# 2806x_CLA_Type0_Registers register map
Vendor: Texas Instruments
Peripheral module from a debugger description file (folder C2000).
Address unit: 16 bits
Registers are 16-bit, access not given, no defined reset value unless marked. A register's access mark holds for its fields unless they carry their own. Offsets are as the file gives them; lines under a group give offsets from that group; [hi:lo] are bit positions; {n}, {i} and the like mark numbered series; 'fields as' and 'values as' point back to an identical list; <NAME> marks a mode.

## CLA — CLA1 Registers
0x00 MVECT1 — Task 1 vector
0x01 MVECT2 — Task 2 vector
0x02 MVECT3 — Task 3 vector
0x03 MVECT4 — Task 4 vector
0x04 MVECT5 — Task 5 vector
0x05 MVECT6 — Task 6 vector
0x06 MVECT7 — Task 7 vector
0x07 MVECT8 — Task 8 vector
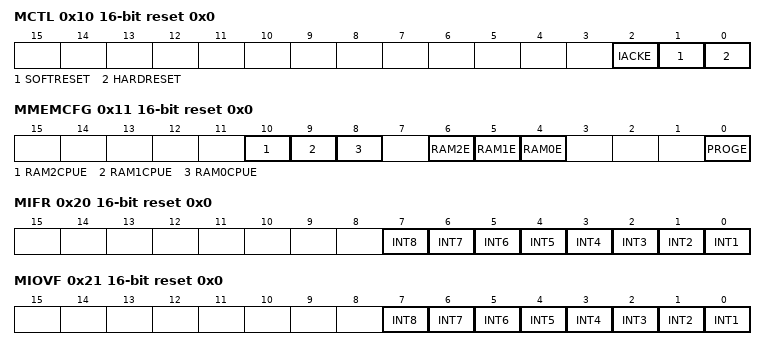
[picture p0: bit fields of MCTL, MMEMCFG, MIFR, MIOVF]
0x10 MCTL rw reset 0x0 — CLA control
  [2] IACKE — IACK enable
  [1] SOFTRESET
  [0] HARDRESET
0x11 MMEMCFG rw reset 0x0 — CLA memory configuration
  [10] RAM2CPUE — RAM2 CPU Access enable
  [9] RAM1CPUE — RAM1 CPU Access enable
  [8] RAM0CPUE — RAM0 CPU Access enable
  [6] RAM2E — RAM2 enable
  [5] RAM1E — RAM1 enable
  [4] RAM0E — RAM0 enable
  [0] PROGE — Program memory enable
0x14 MPISRCSEL1 32-bit — CLA interrupt source select
0x20 MIFR ro reset 0x0 — CLA interrupt flag
  [n-1] INT{n} (n=1..8) — Interrupt {n} flag bit
0x21 MIOVF ro reset 0x0 — CLA interrupt overflow flag
  [n-1] INT{n} (n=1..8) — Interrupt {n} overflow bit
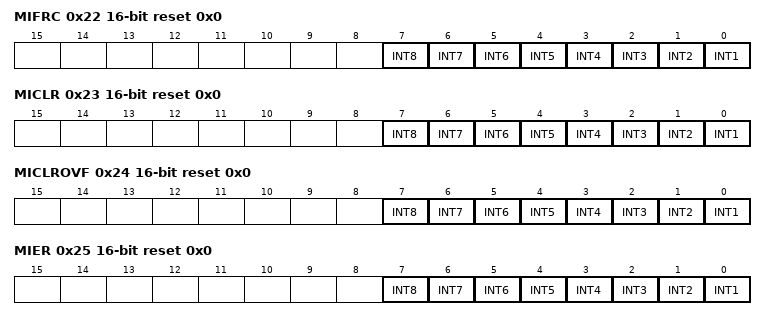
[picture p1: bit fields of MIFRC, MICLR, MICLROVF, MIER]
0x22 MIFRC rw reset 0x0 — CLA interrupt force
  [n-1] INT{n} (n=1..8) — Interrupt {n} force bit
0x23 MICLR rw reset 0x0 — CLA interrupt flag clear
  [n-1] INT{n} (n=1..8) — Interrupt {n} clear bit
0x24 MICLROVF rw reset 0x0 — CLA interrupt overflow flag clear
  [n-1] INT{n} (n=1..8) — Interrupt {n} overflow clear bit
0x25 MIER rw reset 0x0 — CLA interrupt enable
  [n-1] INT{n} (n=1..8) — Interrupt {n} enable bit
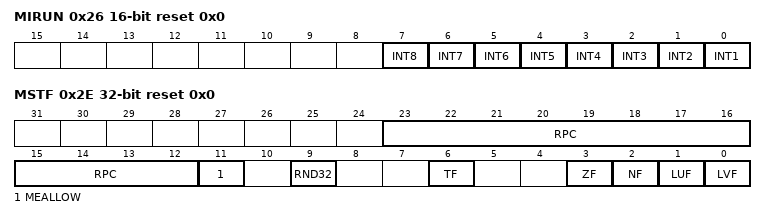
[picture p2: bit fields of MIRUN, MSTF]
0x26 MIRUN rw reset 0x0 — CLA interrupt run status
  [n-1] INT{n} (n=1..8) — Interrupt {n} run status
0x28 MPC — CLA program counter
0x2A MAR0 — CLA auxillary register 0
0x2B MAR1 — CLA auxillary register 1
0x2E MSTF 32-bit ro reset 0x0 — CLA floating-point status register
  [23:12] RPC — Return PC
  [11] MEALLOW — Protected write
  [9] RND32 — Rounding mode
  [6] TF — Test flag
  [3] ZF — Zero flag
  [2] NF — Negative flag
  [1] LUF — Underflow flag
  [0] LVF — Overflow flag
{0x30+4i} MR{i} 32-bit (i=0..3) — CLA result register {i}
